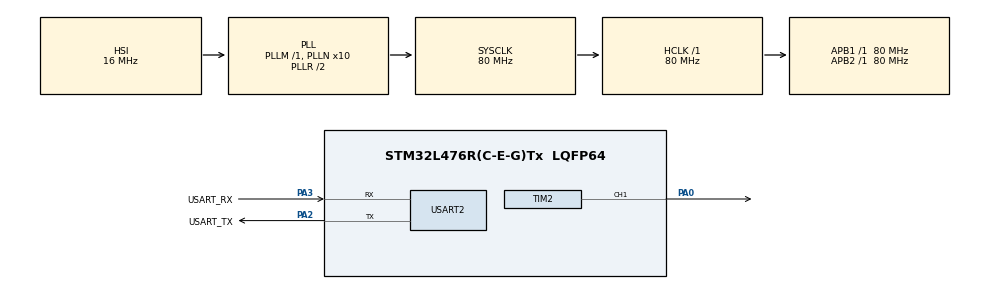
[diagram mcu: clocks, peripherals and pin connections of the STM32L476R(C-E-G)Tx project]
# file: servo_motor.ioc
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Mcu.Family=STM32L4
RCC.MSI_VALUE=4000000
RCC.PLLSourceVirtual=RCC_PLLSOURCE_HSI
PA14\ (JTCK-SWCLK).Mode=Serial_Wire
PA2.GPIO_PuPd=GPIO_NOPULL
VP_SYS_VS_tim6.Mode=TIM6
SH.S_TIM2_CH1.0=TIM2_CH1,PWM Generation1 CH1
RCC.CortexFreq_Value=80000000
FREERTOS.Tasks01=servoTask,8,128,StartServoTask,Default,NULL,Dynamic,NULL,NULL
NVIC.TIM6_DAC_IRQn=true\:0\:0\:false\:false\:true\:false\:false\:true
PH0-OSC_IN\ (PH0).Signal=RCC_OSC_IN
PA3.GPIO_PuPd=GPIO_NOPULL
PA2.GPIO_Speed=GPIO_SPEED_FREQ_VERY_HIGH
PC15-OSC32_OUT\ (PC15).Signal=RCC_OSC32_OUT
PB3\ (JTDO-TRACESWO).GPIO_Label=SWO
PA14\ (JTCK-SWCLK).GPIO_Label=TCK
PC15-OSC32_OUT\ (PC15).Mode=LSE-External-Oscillator
PA3.GPIO_Speed=GPIO_SPEED_FREQ_VERY_HIGH
PH1-OSC_OUT\ (PH1).Signal=RCC_OSC_OUT
RCC.SYSCLKSource=RCC_SYSCLKSOURCE_PLLCLK
ProjectManager.StackSize=0x400
PB3\ (JTDO-TRACESWO).Signal=SYS_JTDO-SWO
PC14-OSC32_IN\ (PC14).Mode=LSE-External-Oscillator
VP_FREERTOS_VS_CMSIS_V2.Mode=CMSIS_V2
PA14\ (JTCK-SWCLK).Signal=SYS_JTCK-SWCLK
PA3.Mode=Asynchronous
ProjectManager.TargetToolchain=STM32CubeIDE
PA3.GPIO_Mode=GPIO_MODE_AF_PP
RCC.HCLKFreq_Value=80000000
RCC.APB2TimFreq_Value=80000000
RCC.USBFreq_Value=64000000
RCC.AHBFreq_Value=80000000
RCC.HSE_VALUE=8000000
board=NUCLEO-L476RG
USART2.VirtualMode-Asynchronous=VM_ASYNC
RCC.VCOOutputFreq_Value=160000000
RCC.APB2Freq_Value=80000000
PA13\ (JTMS-SWDIO).GPIO_Label=TMS
VP_TIM2_VS_ClockSourceINT.Mode=Internal
RCC.ADCFreq_Value=64000000
TIM2.Channel-PWM\ Generation1\ CH1=TIM_CHANNEL_1
TIM2.Period=20000 - 1
Mcu.Name=STM32L476R(C-E-G)Tx
PA2.Signal=USART2_TX
PA0.Signal=S_TIM2_CH1
PA13\ (JTMS-SWDIO).Mode=Serial_Wire
RCC.SYSCLKFreq_VALUE=80000000
Mcu.Package=LQFP64
TIM2.Prescaler=80 - 1
NVIC.TimeBase=TIM6_DAC_IRQn
PC14-OSC32_IN\ (PC14).Signal=RCC_OSC32_IN
PA2.GPIO_Label=USART_TX
NVIC.TimeBaseIP=TIM6
ProjectManager.HeapSize=0x200
RCC.HSI_VALUE=16000000
NVIC.PriorityGroup=NVIC_PRIORITYGROUP_4
RCC.PLLN=10
RCC.APB1TimFreq_Value=80000000
PA2.Mode=Asynchronous
PA13\ (JTMS-SWDIO).Signal=SYS_JTMS-SWDIO
RCC.APB1Freq_Value=80000000
PA3.GPIO_Label=USART_RX
PA3.Signal=USART2_RX
PA2.GPIO_Mode=GPIO_MODE_AF_PP

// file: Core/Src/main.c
/* USER CODE BEGIN Header */
/**
  ******************************************************************************
  * @file           : main.c
  * @brief          : Main program body
  ******************************************************************************
  * @attention
  *
  * <h2><center>&copy; Copyright (c) 2021 STMicroelectronics.
  * All rights reserved.</center></h2>
  *
  * This software component is licensed by ST under BSD 3-Clause license,
  * the "License"; You may not use this file except in compliance with the
  * License. You may obtain a copy of the License at:
  *                        opensource.org/licenses/BSD-3-Clause
  *
  ******************************************************************************
  */
/* USER CODE END Header */
#include "main.h"
#include "cmsis_os.h"

/* USER CODE BEGIN Includes */
#include <stdio.h>
/* USER CODE END Includes */

/* USER CODE BEGIN PTD */
#ifdef __GNUC__
	#define PUTCHAR_PROTOTYPE int __io_putchar(int ch)
#else
	#define PUTCHAR_PROTOTYPE int fputc(int ch, FILE *f)
#endif /* __GNUC__ */
/* USER CODE END PTD */

TIM_HandleTypeDef htim2;

UART_HandleTypeDef huart2;

/* Definitions for servoTask */
osThreadId_t servoTaskHandle;
const osThreadAttr_t servoTask_attributes = {
  .name = "servoTask",
  .stack_size = 128 * 4,
  .priority = (osPriority_t) osPriorityLow,
};

void SystemClock_Config(void);
static void MX_GPIO_Init(void);
static void MX_USART2_UART_Init(void);
static void MX_TIM2_Init(void);
void StartServoTask(void *argument);

int main(void)
{

  /* MCU Configuration--------------------------------------------------------*/

  /* Reset of all peripherals, Initializes the Flash interface and the Systick. */
  HAL_Init();

  /* Configure the system clock */
  SystemClock_Config();

  /* Initialize all configured peripherals */
  MX_GPIO_Init();
  MX_USART2_UART_Init();
  MX_TIM2_Init();
  /* USER CODE BEGIN 2 */

  // Start PWM
  HAL_TIM_PWM_Start(&htim2, TIM_CHANNEL_1);
  htim2.Instance->CCR1 = htim2.Init.Period/2; // Capture Compare Register Value: 50/100 is 50% duty cycle

  /* USER CODE END 2 */

  /* Init scheduler */
  osKernelInitialize();

  /* Create the thread(s) */
  /* creation of servoTask */
  servoTaskHandle = osThreadNew(StartServoTask, NULL, &servoTask_attributes);

  /* Start scheduler */
  osKernelStart();

  /* We should never get here as control is now taken by the scheduler */
  /* Infinite loop */
  for (;;)
  {

  }
}

void SystemClock_Config(void)
{
  RCC_OscInitTypeDef RCC_OscInitStruct = {0};
  RCC_ClkInitTypeDef RCC_ClkInitStruct = {0};
  RCC_PeriphCLKInitTypeDef PeriphClkInit = {0};

  /** Initializes the RCC Oscillators according to the specified parameters
  * in the RCC_OscInitTypeDef structure.
  */
  RCC_OscInitStruct.OscillatorType = RCC_OSCILLATORTYPE_HSI;
  RCC_OscInitStruct.HSIState = RCC_HSI_ON;
  RCC_OscInitStruct.HSICalibrationValue = RCC_HSICALIBRATION_DEFAULT;
  RCC_OscInitStruct.PLL.PLLState = RCC_PLL_ON;
  RCC_OscInitStruct.PLL.PLLSource = RCC_PLLSOURCE_HSI;
  RCC_OscInitStruct.PLL.PLLM = 1;
  RCC_OscInitStruct.PLL.PLLN = 10;
  RCC_OscInitStruct.PLL.PLLP = RCC_PLLP_DIV7;
  RCC_OscInitStruct.PLL.PLLQ = RCC_PLLQ_DIV2;
  RCC_OscInitStruct.PLL.PLLR = RCC_PLLR_DIV2;
  if (HAL_RCC_OscConfig(&RCC_OscInitStruct) != HAL_OK)
  {
    Error_Handler();
  }
  /** Initializes the CPU, AHB and APB buses clocks
  */
  RCC_ClkInitStruct.ClockType = RCC_CLOCKTYPE_HCLK|RCC_CLOCKTYPE_SYSCLK
                              |RCC_CLOCKTYPE_PCLK1|RCC_CLOCKTYPE_PCLK2;
  RCC_ClkInitStruct.SYSCLKSource = RCC_SYSCLKSOURCE_PLLCLK;
  RCC_ClkInitStruct.AHBCLKDivider = RCC_SYSCLK_DIV1;
  RCC_ClkInitStruct.APB1CLKDivider = RCC_HCLK_DIV1;
  RCC_ClkInitStruct.APB2CLKDivider = RCC_HCLK_DIV1;

  if (HAL_RCC_ClockConfig(&RCC_ClkInitStruct, FLASH_LATENCY_4) != HAL_OK)
  {
    Error_Handler();
  }
  PeriphClkInit.PeriphClockSelection = RCC_PERIPHCLK_USART2;
  PeriphClkInit.Usart2ClockSelection = RCC_USART2CLKSOURCE_PCLK1;
  if (HAL_RCCEx_PeriphCLKConfig(&PeriphClkInit) != HAL_OK)
  {
    Error_Handler();
  }
  /** Configure the main internal regulator output voltage
  */
  if (HAL_PWREx_ControlVoltageScaling(PWR_REGULATOR_VOLTAGE_SCALE1) != HAL_OK)
  {
    Error_Handler();
  }
}

static void MX_TIM2_Init(void)
{

  TIM_ClockConfigTypeDef sClockSourceConfig = {0};
  TIM_MasterConfigTypeDef sMasterConfig = {0};
  TIM_OC_InitTypeDef sConfigOC = {0};

  htim2.Instance = TIM2;
  htim2.Init.Prescaler = 80 - 1;
  htim2.Init.CounterMode = TIM_COUNTERMODE_UP;
  htim2.Init.Period = 20000 - 1;
  htim2.Init.ClockDivision = TIM_CLOCKDIVISION_DIV1;
  htim2.Init.AutoReloadPreload = TIM_AUTORELOAD_PRELOAD_DISABLE;
  if (HAL_TIM_Base_Init(&htim2) != HAL_OK)
  {
    Error_Handler();
  }
  sClockSourceConfig.ClockSource = TIM_CLOCKSOURCE_INTERNAL;
  if (HAL_TIM_ConfigClockSource(&htim2, &sClockSourceConfig) != HAL_OK)
  {
    Error_Handler();
  }
  if (HAL_TIM_PWM_Init(&htim2) != HAL_OK)
  {
    Error_Handler();
  }
  sMasterConfig.MasterOutputTrigger = TIM_TRGO_RESET;
  sMasterConfig.MasterSlaveMode = TIM_MASTERSLAVEMODE_DISABLE;
  if (HAL_TIMEx_MasterConfigSynchronization(&htim2, &sMasterConfig) != HAL_OK)
  {
    Error_Handler();
  }
  sConfigOC.OCMode = TIM_OCMODE_PWM1;
  sConfigOC.Pulse = 0;
  sConfigOC.OCPolarity = TIM_OCPOLARITY_HIGH;
  sConfigOC.OCFastMode = TIM_OCFAST_DISABLE;
  if (HAL_TIM_PWM_ConfigChannel(&htim2, &sConfigOC, TIM_CHANNEL_1) != HAL_OK)
  {
    Error_Handler();
  }
  HAL_TIM_MspPostInit(&htim2);

}

static void MX_USART2_UART_Init(void)
{

  huart2.Instance = USART2;
  huart2.Init.BaudRate = 115200;
  huart2.Init.WordLength = UART_WORDLENGTH_8B;
  huart2.Init.StopBits = UART_STOPBITS_1;
  huart2.Init.Parity = UART_PARITY_NONE;
  huart2.Init.Mode = UART_MODE_TX_RX;
  huart2.Init.HwFlowCtl = UART_HWCONTROL_NONE;
  huart2.Init.OverSampling = UART_OVERSAMPLING_16;
  huart2.Init.OneBitSampling = UART_ONE_BIT_SAMPLE_DISABLE;
  huart2.AdvancedInit.AdvFeatureInit = UART_ADVFEATURE_NO_INIT;
  if (HAL_UART_Init(&huart2) != HAL_OK)
  {
    Error_Handler();
  }

}

static void MX_GPIO_Init(void)
{

  /* GPIO Ports Clock Enable */
  __HAL_RCC_GPIOC_CLK_ENABLE();
  __HAL_RCC_GPIOH_CLK_ENABLE();
  __HAL_RCC_GPIOA_CLK_ENABLE();
  __HAL_RCC_GPIOB_CLK_ENABLE();

}

/* USER CODE BEGIN 4 */
PUTCHAR_PROTOTYPE
{
	HAL_UART_Transmit(&huart2, (uint8_t *)&ch, 1, 0xFFFF);
	return ch;
}
/* USER CODE END 4 */

void StartServoTask(void *argument)
{
  /* USER CODE BEGIN 5 */
	uint8_t mode = 0;

  /* Infinite loop */
  for(;;)
  {
  	/*
    htim2.Instance->CCR1 += 50; // Capture Compare Register Value: 50/100 is 50% duty cycle
    if (htim2.Instance->CCR1 > 3500)
    {
    	htim2.Instance->CCR1 = 500;
    }
    else if (htim2.Instance->CCR1 < 500)
    {
    	htim2.Instance->CCR1 = 500;
    }

    printf("%lu\r\n", (uint32_t)htim2.Instance->CCR1);
    */

  	/*
  	if (htim2.Instance->CCR1 == 2500)
  	{
  		htim2.Instance->CCR1 = 1166;
  	}
  	else
  	{
  		htim2.Instance->CCR1 = 2500;
  	}
  	*/

  	// 2460, 1815, 1170
  	// 2465, 1815, 1165

  	/*
  	if (htim2.Instance->CCR1 == 2460)
  	{
  	  htim2.Instance->CCR1 = 1815;
  	}
  	else if (htim2.Instance->CCR1 == 1815)
  	{
  	  htim2.Instance->CCR1 = 1170;
  	}
  	else
  	{
  	  htim2.Instance->CCR1 = 2460;
  	}*/

  	/*
  	if (htim2.Instance->CCR1 == 2460)
  	{
  	  htim2.Instance->CCR1 = 1170;
  	}
  	else
  	{
  	  htim2.Instance->CCR1 = 2460;
  	}
  	 */

//  	htim2.Instance->CCR1 = 1815;

  	if (mode == 0)
  	{
  	  htim2.Instance->CCR1 = 2460;

  	}
  	else if (mode == 1)
  	{
  		htim2.Instance->CCR1 = 1815;
  	}
  	else if (mode == 2)
  	{
  		htim2.Instance->CCR1 = 1170;
  	}
  	else if (mode == 3)
  	{
    	htim2.Instance->CCR1 = 1815;
  	}

  	mode = (mode + 1) % 4;
    printf("%lu\r\n", (uint32_t)htim2.Instance->CCR1);

    osDelay(1000);
  }
  /* USER CODE END 5 */
}

 /**
  * @brief  Period elapsed callback in non blocking mode
  * @note   This function is called  when TIM6 interrupt took place, inside
  * HAL_TIM_IRQHandler(). It makes a direct call to HAL_IncTick() to increment
  * a global variable "uwTick" used as application time base.
  * @param  htim : TIM handle
  * @retval None
  */
void HAL_TIM_PeriodElapsedCallback(TIM_HandleTypeDef *htim)
{
  if (htim->Instance == TIM6) {
    HAL_IncTick();
  }
}

void Error_Handler(void)
{
  __disable_irq();
  while (1)
  {
  }
}

/************************ (C) COPYRIGHT STMicroelectronics *****END OF FILE****/
